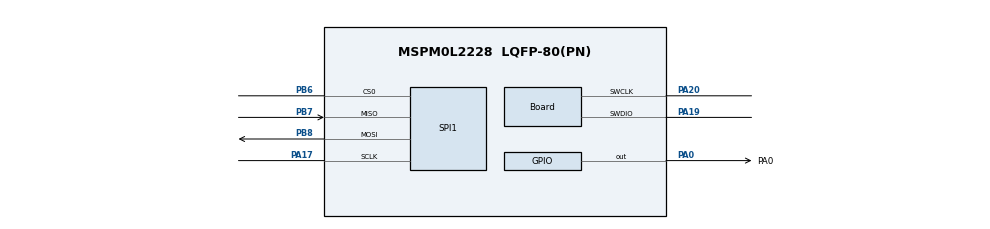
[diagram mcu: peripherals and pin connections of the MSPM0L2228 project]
//@cliArgs --device "MSPM0L222X" --package "LQFP-80(PN)" --part "Default"
//@v2CliArgs --device "MSPM0L2228" --package "LQFP-80(PN)"
// @cliArgs --board /ti/boards/LP_MSPM0L2228 --rtos nortos

/**
 * Import the modules used in this configuration.
 */
const Board = scripting.addModule("/ti/driverlib/Board");
const GPIO  = scripting.addModule("/ti/driverlib/GPIO", {}, false);
const GPIO1 = GPIO.addInstance();
const GPIO2 = GPIO.addInstance();
const GPIO3 = GPIO.addInstance();
const SPI   = scripting.addModule("/ti/driverlib/SPI", {}, false);
const SPI1  = SPI.addInstance();

/**
 * Write custom configuration values to the imported modules.
 */
const gate6  = system.clockTree["MFCLKGATE"];
gate6.enable = true;

Board.peripheral.$assign          = "DEBUGSS";
Board.peripheral.swclkPin.$assign = "PA20";
Board.peripheral.swdioPin.$assign = "PA19";

GPIO1.port                          = "PORTA";
GPIO1.$name                         = "GPIO_LED";
GPIO1.associatedPins.create(2);
GPIO1.associatedPins[0].$name       = "PA0";
GPIO1.associatedPins[0].assignedPin = "0";
GPIO1.associatedPins[0].pin.$assign = "PA0";
GPIO1.associatedPins[1].$name       = "Error";
GPIO1.associatedPins[1].assignedPin = "23";

GPIO2.$name                          = "GPIO_BSL";
GPIO2.associatedPins.create(2);
GPIO2.associatedPins[0].$name        = "NRST";
GPIO2.associatedPins[0].initialValue = "SET";
GPIO2.associatedPins[0].assignedPort = "PORTB";
GPIO2.associatedPins[0].assignedPin  = "5";
GPIO2.associatedPins[1].$name        = "Invoke";
GPIO2.associatedPins[1].assignedPort = "PORTB";
GPIO2.associatedPins[1].assignedPin  = "4";

GPIO3.$name                          = "GPIO_Button";
GPIO3.associatedPins[0].direction    = "INPUT";
GPIO3.associatedPins[0].$name        = "PIN_0";
GPIO3.associatedPins[0].assignedPin  = "18";
GPIO3.associatedPins[0].assignedPort = "PORTA";

SPI1.$name                      = "SPI_0";
SPI1.rxFifoThreshold            = "DL_SPI_RX_FIFO_LEVEL_ONE_FRAME";
SPI1.targetBitRate              = 1000000;
SPI1.spiClkSrc                  = "MFCLK";
SPI1.txFifoThreshold            = "DL_SPI_TX_FIFO_LEVEL_ONE_FRAME";
SPI1.peripheral.$assign         = "SPI1";
SPI1.peripheral.sclkPin.$assign = "PA17";
SPI1.peripheral.mosiPin.$assign = "PB8";
SPI1.peripheral.misoPin.$assign = "PB7";
SPI1.peripheral.cs0Pin.$assign  = "PB6";

const SYSCTL       = scripting.addModule("/ti/driverlib/SYSCTL", {}, false);
SYSCTL.clockTreeEn = true;

const ProjectConfig              = scripting.addModule("/ti/project_config/ProjectConfig", {}, false);
ProjectConfig.migrationCondition = true;
